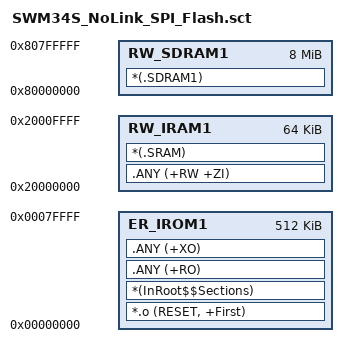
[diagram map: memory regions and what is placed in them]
; *************************************************************
; *** Scatter-Loading Description File generated by uVision ***
; *************************************************************


;UseBoot-APP
;LR_IROM1 0x00010000 0x00070000  {    ; load region size_region
;  ER_IROM1 0x00010000 0x00070000  {  ; load address = execution address

;General-APP
LR_IROM1 0x00000000 0x00080000  {    ; load region size_region
  ER_IROM1 0x00000000 0x00080000  {  ; load address = execution address

   *.o (RESET, +First)
   *(InRoot$$Sections)
   .ANY (+RO)
   .ANY (+XO)
  }
  RW_IRAM1 0x20000000 0x00010000  {  ; RW data
   .ANY (+RW +ZI)
   *(.SRAM)
  }
  RW_SDRAM1 0x80000000 0x00800000  { ; RW data
    *(.SDRAM1)
  }
;  0x00200000
;  RW_SDRAM2 0x80200000 0x00600000  { ; RW data
;    *(.SDRAM2)
;  }
}
